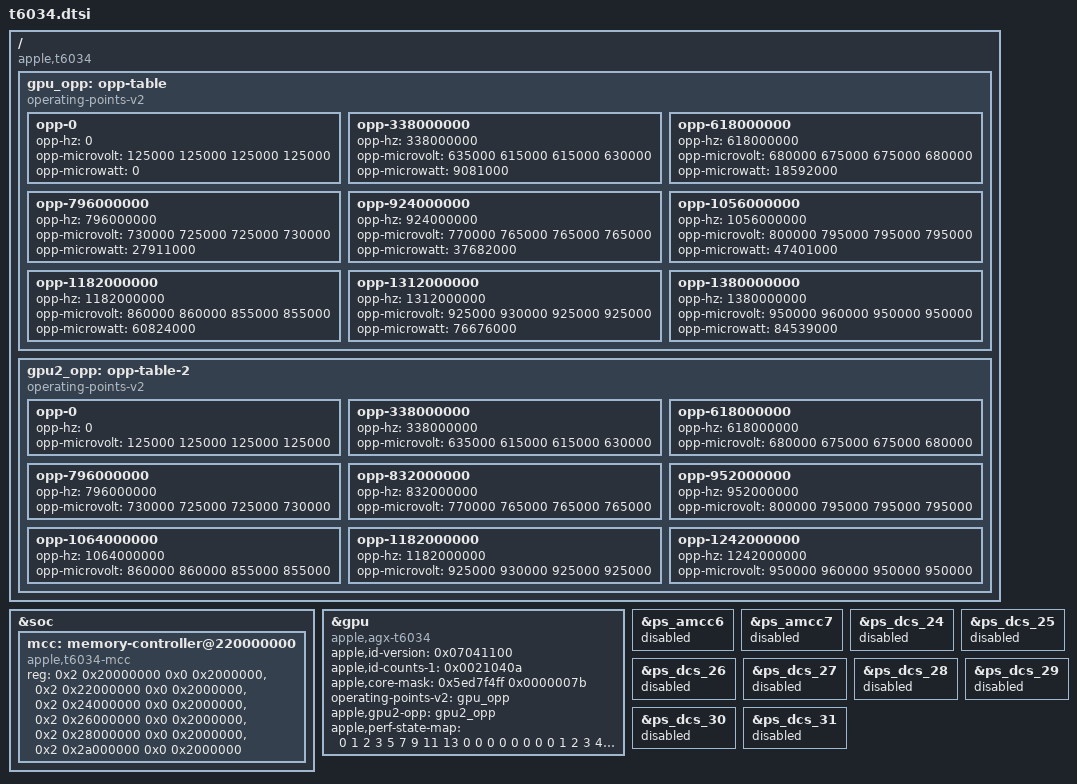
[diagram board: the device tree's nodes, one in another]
// SPDX-License-Identifier: GPL-2.0+ OR MIT
/*
 * Apple T6034 "M3 Max" SoC
 *
 * Copyright The Asahi Linux Contributors
 */

#include "t6031.dtsi"
#include "t603x-gpu.dtsi"

/ {
	compatible = "apple,t6034", "apple,arm-platform";

	/* j514map's GPU perf-state tables (spec/agx-g15c/chip-config.md, the
	 * GPU perf-state tables): the driver keeps them, and checks the tables
	 * it builds from m1n1's apple,perf-states against them. The live ADT perf-states are 4 tables (one per
	 * cluster) x 14 rows of {Hz, mV}, sharing the frequencies; the
	 * Fender state maps (MRR 0x101400/0x101480, read 2026-10-12) pick the
	 * rows of the two tables the kext's createMGPUPerfStateTables builds:
	 * gpu_opp (table A, the GPU table) and gpu2_opp (table B).
	 * opp-microvolt = the four tables' volts. opp-microwatt = the G15X
	 * populateMaximumPerformancePower's per-state power (the clusters'
	 * V * min(V^1.2 * 19.9 * MHz * nUSC/10, 34000) + CS/4, summed;
	 * computed offline, no FPU in the kernel); the top state's is P,
	 * the GPU max power (84539).
	 */
	gpu_opp: opp-table {
		compatible = "operating-points-v2";
		opp-0 {
			opp-hz = /bits/ 64 <0>;
			opp-microvolt = <125000 125000 125000 125000>;
			opp-microwatt = <0>;
		};
		opp-338000000 {
			opp-hz = /bits/ 64 <338000000>;
			opp-microvolt = <635000 615000 615000 630000>;
			opp-microwatt = <9081000>;
		};
		opp-618000000 {
			opp-hz = /bits/ 64 <618000000>;
			opp-microvolt = <680000 675000 675000 680000>;
			opp-microwatt = <18592000>;
		};
		opp-796000000 {
			opp-hz = /bits/ 64 <796000000>;
			opp-microvolt = <730000 725000 725000 730000>;
			opp-microwatt = <27911000>;
		};
		opp-924000000 {
			opp-hz = /bits/ 64 <924000000>;
			opp-microvolt = <770000 765000 765000 765000>;
			opp-microwatt = <37682000>;
		};
		opp-1056000000 {
			opp-hz = /bits/ 64 <1056000000>;
			opp-microvolt = <800000 795000 795000 795000>;
			opp-microwatt = <47401000>;
		};
		opp-1182000000 {
			opp-hz = /bits/ 64 <1182000000>;
			opp-microvolt = <860000 860000 855000 855000>;
			opp-microwatt = <60824000>;
		};
		opp-1312000000 {
			opp-hz = /bits/ 64 <1312000000>;
			opp-microvolt = <925000 930000 925000 925000>;
			opp-microwatt = <76676000>;
		};
		opp-1380000000 {
			opp-hz = /bits/ 64 <1380000000>;
			opp-microvolt = <950000 960000 950000 950000>;
			opp-microwatt = <84539000>;
		};
	};

	gpu2_opp: opp-table-2 {
		compatible = "operating-points-v2";
		opp-0 {
			opp-hz = /bits/ 64 <0>;
			opp-microvolt = <125000 125000 125000 125000>;
		};
		opp-338000000 {
			opp-hz = /bits/ 64 <338000000>;
			opp-microvolt = <635000 615000 615000 630000>;
		};
		opp-618000000 {
			opp-hz = /bits/ 64 <618000000>;
			opp-microvolt = <680000 675000 675000 680000>;
		};
		opp-796000000 {
			opp-hz = /bits/ 64 <796000000>;
			opp-microvolt = <730000 725000 725000 730000>;
		};
		opp-832000000 {
			opp-hz = /bits/ 64 <832000000>;
			opp-microvolt = <770000 765000 765000 765000>;
		};
		opp-952000000 {
			opp-hz = /bits/ 64 <952000000>;
			opp-microvolt = <800000 795000 795000 795000>;
		};
		opp-1064000000 {
			opp-hz = /bits/ 64 <1064000000>;
			opp-microvolt = <860000 860000 855000 855000>;
		};
		opp-1182000000 {
			opp-hz = /bits/ 64 <1182000000>;
			opp-microvolt = <925000 930000 925000 925000>;
		};
		opp-1242000000 {
			opp-hz = /bits/ 64 <1242000000>;
			opp-microvolt = <950000 960000 950000 950000>;
		};
	};

};

&soc {
	/* The six AMCCs of the live ADT's mcc node (reg[3..8], bus 0x2000_0000
	 * + n * 0x200_0000); t6031 has eight.
	 */
	mcc: memory-controller@220000000 {
		compatible = "apple,t6034-mcc", "apple,t6031-mcc";
		reg = <0x2 0x20000000 0x0 0x2000000>,
			<0x2 0x22000000 0x0 0x2000000>,
			<0x2 0x24000000 0x0 0x2000000>,
			<0x2 0x26000000 0x0 0x2000000>,
			<0x2 0x28000000 0x0 0x2000000>,
			<0x2 0x2a000000 0x0 0x2000000>;
	};
};

&gpu {
	compatible = "apple,agx-t6034", "gpu,t6034";

	/* j514map's G15 ID (spec: agx-g15c/gpu-id.md), which the driver reads
	 * from the GPU (the Fender block, sgx reg[1], GFX on) and checks this
	 * copy against. id-version +0x4000: gen 7, variant 4 (G15C), revision
	 * B1. id-counts-1 +0x4010: 10 cores x 4 clusters x 1 die. core-mask:
	 * the per-core enable mask, MRR +0x101500 (u64, 40 bits for 4 x 10);
	 * its popcount is the kext's gpu-core-count, 30.
	 */
	apple,id-version = <0x07041100>;
	apple,id-counts-1 = <0x0021040a>;
	apple,core-mask = <0x5ed7f4ff 0x0000007b>;

	operating-points-v2 = <&gpu_opp>;
	apple,gpu2-opp = <&gpu2_opp>;
	/* The perf-state map nibbles (Fender MRR +0x101400…0x10141c, then
	 * +0x101480…0x10149c; [3:0] and [19:16] of each word), live.
	 */
	apple,perf-state-map = <0 1 2 3 5 7 9 11 13 0 0 0 0 0 0 0
		0 1 2 3 4 6 8 10 12 0 0 0 0 0 0 0>;
};

// Disable power-states for memory channels not present on the 14-core variant.
&ps_amcc6 {
	status = "disabled";
};

&ps_amcc7 {
	status = "disabled";
};

&ps_dcs_24 {
	status = "disabled";
};

&ps_dcs_25 {
	status = "disabled";
};

&ps_dcs_26 {
	status = "disabled";
};

&ps_dcs_27 {
	status = "disabled";
};

&ps_dcs_28 {
	status = "disabled";
};

&ps_dcs_29 {
	status = "disabled";
};

&ps_dcs_30 {
	status = "disabled";
};

&ps_dcs_31 {
	status = "disabled";
};
